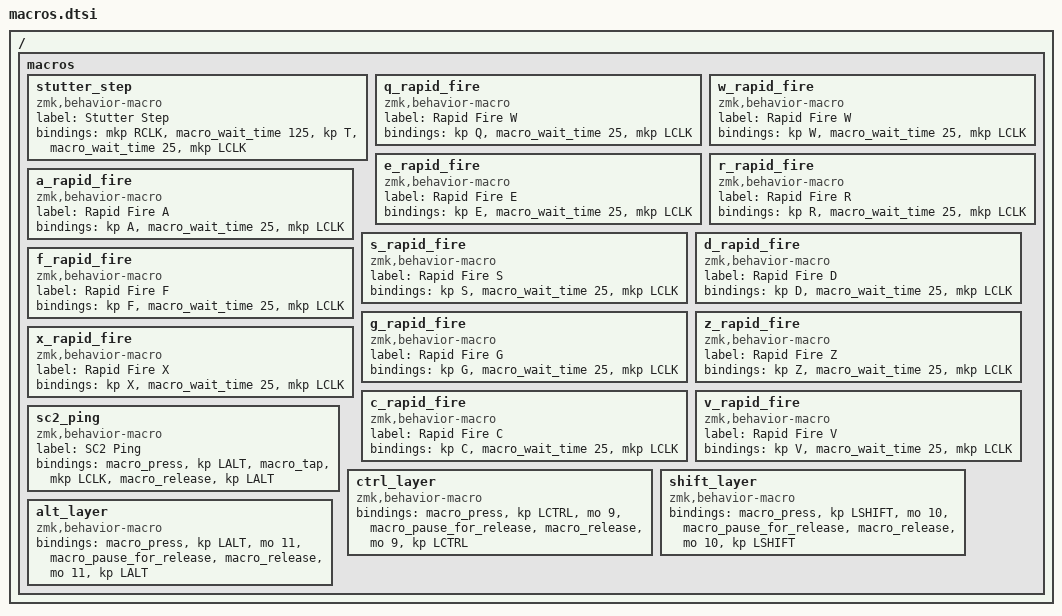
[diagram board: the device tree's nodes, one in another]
/ {
    macros {
        stutter_step: stutter_step {
            label = "Stutter Step";
            compatible = "zmk,behavior-macro";
            #binding-cells = <0>;
            bindings = <
                &mkp RCLK
                &macro_wait_time 125
                &kp T
                &macro_wait_time 25
                &mkp LCLK
            >;
        };

        q_rapid_fire: q_rapid_fire {
            label = "Rapid Fire W";
            compatible = "zmk,behavior-macro";
            #binding-cells = <0>;
            bindings = <
                &kp Q                // Press Q ability
                &macro_wait_time 25  // 25 ms delay
                &mkp LCLK            // Left mouse click
            >;
        };

        w_rapid_fire: w_rapid_fire {
            label = "Rapid Fire W";
            compatible = "zmk,behavior-macro";
            #binding-cells = <0>;
            bindings = <
                &kp W            // Press W ability
                &macro_wait_time 25  // 25 ms delay
                &mkp LCLK            // Left mouse click
            >;
        };

        e_rapid_fire: e_rapid_fire {
            label = "Rapid Fire E";
            compatible = "zmk,behavior-macro";
            #binding-cells = <0>;
            bindings = <
                &kp E            // Press E ability
                &macro_wait_time 25  // 25 ms delay
                &mkp LCLK            // Left mouse click
            >;
        };

        r_rapid_fire: r_rapid_fire {
            label = "Rapid Fire R";
            compatible = "zmk,behavior-macro";
            #binding-cells = <0>;
            bindings = <
                &kp R            // Press R ability
                &macro_wait_time 25  // 25 ms delay
                &mkp LCLK            // Left mouse click
            >;
        };

        a_rapid_fire: a_rapid_fire {
            label = "Rapid Fire A";
            compatible = "zmk,behavior-macro";
            #binding-cells = <0>;
            bindings = <
                &kp A            // Press A ability
                &macro_wait_time 25  // 25 ms delay
                &mkp LCLK            // Left mouse click
            >;
        };

        s_rapid_fire: s_rapid_fire {
            label = "Rapid Fire S";
            compatible = "zmk,behavior-macro";
            #binding-cells = <0>;
            bindings = <
                &kp S            // Press S ability
                &macro_wait_time 25  // 25 ms delay
                &mkp LCLK            // Left mouse click
            >;
        };

        d_rapid_fire: d_rapid_fire {
            label = "Rapid Fire D";
            compatible = "zmk,behavior-macro";
            #binding-cells = <0>;
            bindings = <
                &kp D            // Press D ability
                &macro_wait_time 25  // 25 ms delay
                &mkp LCLK            // Left mouse click
            >;
        };

        f_rapid_fire: f_rapid_fire {
            label = "Rapid Fire F";
            compatible = "zmk,behavior-macro";
            #binding-cells = <0>;
            bindings = <
                &kp F            // Press F ability
                &macro_wait_time 25  // 25 ms delay
                &mkp LCLK            // Left mouse click
            >;
        };

        g_rapid_fire: g_rapid_fire {
            label = "Rapid Fire G";
            compatible = "zmk,behavior-macro";
            #binding-cells = <0>;
            bindings = <
                &kp G            // Press G ability
                &macro_wait_time 25  // 25 ms delay
                &mkp LCLK            // Left mouse click
            >;
        };

        z_rapid_fire: z_rapid_fire {
            label = "Rapid Fire Z";
            compatible = "zmk,behavior-macro";
            #binding-cells = <0>;
            bindings = <
                &kp Z            // Press Z ability
                &macro_wait_time 25  // 25 ms delay
                &mkp LCLK            // Left mouse click
            >;
        };

        x_rapid_fire: x_rapid_fire {
            label = "Rapid Fire X";
            compatible = "zmk,behavior-macro";
            #binding-cells = <0>;
            bindings = <
                &kp X            // Press X ability
                &macro_wait_time 25  // 25 ms delay
                &mkp LCLK            // Left mouse click
            >;
        };

        c_rapid_fire: c_rapid_fire {
            label = "Rapid Fire C";
            compatible = "zmk,behavior-macro";
            #binding-cells = <0>;
            bindings = <
                &kp C            // Press C ability
                &macro_wait_time 25  // 25 ms delay
                &mkp LCLK            // Left mouse click
            >;
        };

        v_rapid_fire: v_rapid_fire {
            label = "Rapid Fire V";
            compatible = "zmk,behavior-macro";
            #binding-cells = <0>;
            bindings = <
                &kp V            // Press V ability
                &macro_wait_time 25  // 25 ms delay
                &mkp LCLK            // Left mouse click
            >;
        };

        sc2_ping: sc2_ping {
            label = "SC2 Ping";
            compatible = "zmk,behavior-macro";
            #binding-cells = <0>;
            bindings = <
                &macro_press &kp LALT      // Hold Alt
                &macro_tap &mkp LCLK       // Left mouse click while Alt held
                &macro_release &kp LALT    // Release Alt
            >;
        };

        ctrl_layer: ctrl_layer {
            compatible = "zmk,behavior-macro";
            #binding-cells = <0>;
            bindings = <
                &macro_press
                &kp LCTRL                    // Hold Ctrl
                &mo 9                        // Activate layer
                &macro_pause_for_release
                &macro_release
                &mo 9                        // Release layer
                &kp LCTRL                    // Release Ctrl
            >;
        };

        shift_layer: shift_layer {
            compatible = "zmk,behavior-macro";
            #binding-cells = <0>;
            bindings = <
                &macro_press
                &kp LSHIFT                   // Hold Shift
                &mo 10                       // Activate layer
                &macro_pause_for_release
                &macro_release
                &mo 10                       // Release layer
                &kp LSHIFT                   // Release Shift
            >;
        };

        alt_layer: alt_layer {
            compatible = "zmk,behavior-macro";
            #binding-cells = <0>;
            bindings = <
                &macro_press
                &kp LALT                     // Hold Alt
                &mo 11                       // Activate layer
                &macro_pause_for_release
                &macro_release
                &mo 11                       // Release layer
                &kp LALT                     // Release Alt
            >;
        };
    };
};
